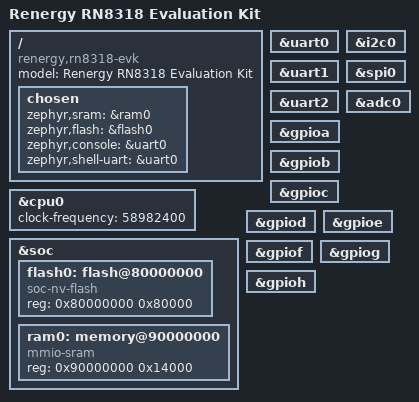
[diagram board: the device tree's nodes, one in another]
/dts-v1/;
#include <renergy/rn8xxx.dtsi>

/ {
	model = "Renergy RN8318 Evaluation Kit";
	compatible = "renergy,rn8318-evk";

	chosen {
		zephyr,sram = &ram0;
		zephyr,flash = &flash0;
		zephyr,console = &uart0;
		zephyr,shell-uart = &uart0;
	};
};

&cpu0 {
	clock-frequency = <58982400>;
};

&soc {
	flash0: flash@80000000 {
		compatible = "soc-nv-flash";
		reg = <0x80000000 0x80000>; /* 512KB */
	};

	ram0: memory@90000000 {
		compatible = "mmio-sram";
		reg = <0x90000000 0x14000>; /* 80KB */
	};
};

/* --- 启用基本通信接口 --- */
&uart0 { status = "okay"; };
&uart1 { status = "okay"; };
&uart2 { status = "okay"; };

&i2c0 { status = "okay"; };
&spi0 { status = "okay"; };

/* --- 启用模拟采样 --- */
&adc0 { status = "okay"; };

/* --- 启用 GPIO 端口 --- */
&gpioa { status = "okay"; };
&gpiob { status = "okay"; };
&gpioc { status = "okay"; };
&gpiod { status = "okay"; };
&gpioe { status = "okay"; };
&gpiof { status = "okay"; };
&gpiog { status = "okay"; };
&gpioh { status = "okay"; };
